# ZB204 register map
Vendor: GS; File version: 1.2
CPU: CM3 r2p0, little endian, MPU, no FPU, VTOR, 3 interrupt priority bits
Registers are 32-bit, read-write, reset 0x0 unless marked. A register's access mark holds for its fields unless they carry their own. Offsets are from the block's base; [hi:lo] are bit positions; {n}, {i} and the like mark numbered series.

## PIT_CHANNEL0 — Programmable Interrupt Timer Modules
Base 0x40070100
Same registers: PIT_CHANNEL1 0x40070110, PIT_CHANNEL2 0x40070120, PIT_CHANNEL3 0x40070130, PIT_CHANNEL4 0x40070140, PIT_CHANNEL5 0x40070150, PIT_CHANNEL6 0x40080100, PIT_CHANNEL7 0x40080110, PIT_CHANNEL8 0x40080120, PIT_CHANNEL9 0x40080130, PIT_CHANNEL10 0x40080140, PIT_CHANNEL11 0x40080150
0x00 LDVAL — Timer Load Value Register
0x04 CVAL — Current Timer Value Register
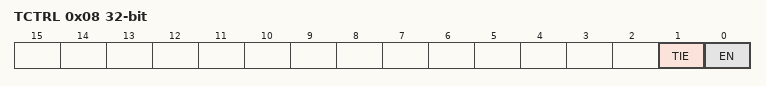
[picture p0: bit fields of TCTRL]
0x08 TCTRL — Timer Control Register
  [1] TIE — Timer Enable Bit
    0=disabled; 1=enabled
  [0] EN — Timer Interrupt Enable Bit
    0=disabled; 1=enabled
0x0C TFLG — Timer Flag Register
  [0] TIF — Time Interrupt Flag
    0=not occurred; 1=occurred

## CCM — Chip Configuration Module
Base 0x40010000
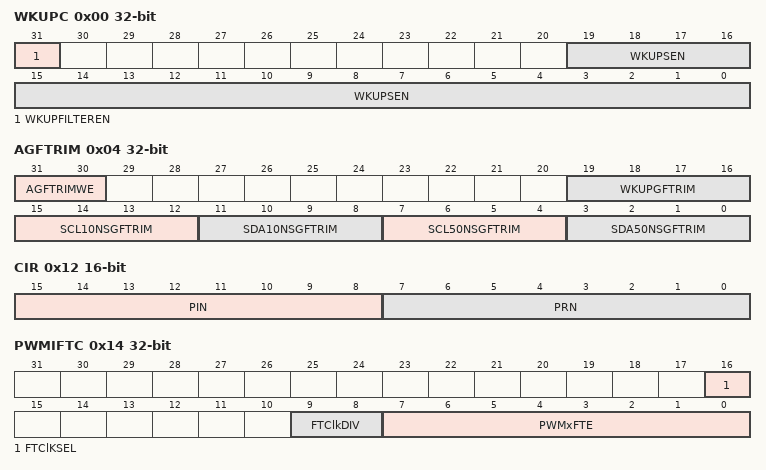
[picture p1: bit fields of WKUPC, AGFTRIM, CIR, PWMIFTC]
0x00 WKUPC — Wakeup Configuration Register
  [31] WKUPFILTEREN — Wakeup Source Filter Enable
    0=enable; 1=enable
  [19:0] WKUPSEN — Wakeup Source Enable
0x04 AGFTRIM — Analog Glitch Filter Trim Value Register
  [31:30] AGFTRIMWE — register write enable
  [19:16] WKUPGFTRIM — Trim value of the wakeup signal glitch filter
  [15:12] SCL10NSGFTRIM — Trim value of the 10ns glitch filter of I2C SCL pin
  [11:8] SDA10NSGFTRIM — Trim value of the 10ns glitch filter of I2C SDA pin
  [7:4] SCL50NSGFTRIM — Trim value of the 50ns glitch filter of I2C SCL pin
  [3:0] SDA50NSGFTRIM — Trim value of the 50ns glitch filter of I2C SDA pin
0x10 CTR 16-bit — Chip Test Register
0x12 CIR 16-bit — Chip Identification Register
  [15:8] PIN — Part Identification Number Field
  [7:0] PRN — Part Revision Number Field
0x14 PWMIFTC — PWM Filter Control
  [16] FTClKSEL — Filter Clock source selection
  [9:8] FTClkDIV — Divide the Filter Clock
  [7:0] PWMxFTE — Enable the PWMx pin input digital glitch filter
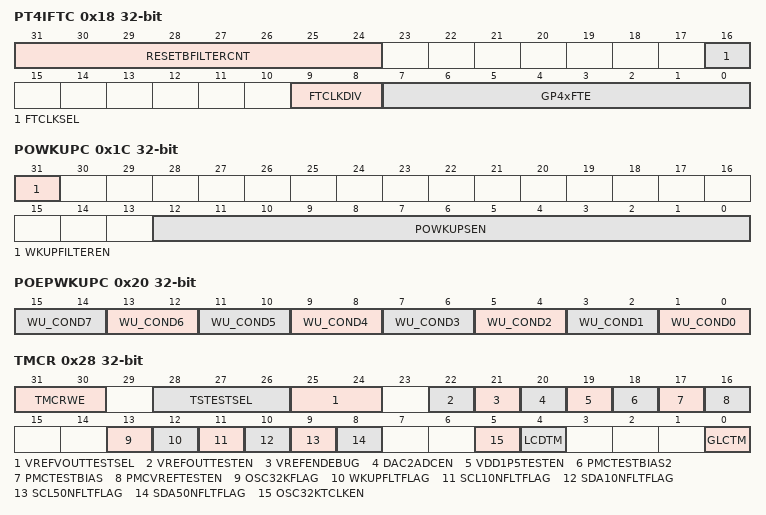
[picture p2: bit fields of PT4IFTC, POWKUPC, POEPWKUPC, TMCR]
0x18 PT4IFTC — PORT4 resetb Filter Control
  [31:24] RESETBFILTERCNT — Resetb Filter Counter Value
  [16] FTCLKSEL — Filter Clock source selection
  [9:8] FTCLKDIV — Divide the Filter Clock by (FTClkDIV+1)
  [7:0] GP4xFTE — Enable the GPIO4[x] pin input digital glitch filter
0x1C POWKUPC — PowerOff Mode Wakeup Configuration Register
  [31] WKUPFILTEREN — Wakeup Source Filter Enable
  [12:0] POWKUPSEN — PowerOff Wakeup Source Enable
0x20 POEPWKUPC — PowerOff Mode External Pins Wakeup Condition Register
  [2n+1:2n] WU_COND{n} (n=0..7) — WakeUp Cond
0x24 POEPWKUPF — PowerOff Mode External Pins Wakeup Flag Register
  [7:0] EPWKUPF — GPIO4x meets the wakeup condition
0x28 TMCR — Test Mode Register
  [31:30] TMCRWE — register write enable
  [28:26] TSTESTSEL — Select TS Test signal to sensebus
  [25:24] VREFVOUTTESTSEL — Select VREF Test signal to sensebus
  [22] VREFOUTTESTEN
  [21] VREFENDEBUG
  [20] DAC2ADCEN
  [19] VDD1P5TESTEN
  [18] PMCTESTBIAS2
  [17] PMCTESTBIAS
  [16] PMCVREFTESTEN
  [13] OSC32KFLAG — OSC32K Glitch Flag
  [12] WKUPFLTFLAG — Wakeup Source Glitch Filter Flag
  [11] SCL10NFLTFLAG — SCL 10ns Glitch Filter Flag
  [10] SDA10NFLTFLAG — SDA 10ns Glitch Filter Flag
  [9] SCL50NFLTFLAG — SCL 50ns Glitch Filter Flag
  [8] SDA50NFLTFLAG — SDA 50ns Glitch Filter Flag
  [5] OSC32KTCLKEN — Enable internal clock test of OSC32K
  [4] LCDTM — LCD Test Mode
  [0] GLCTM — Enable The Glitch Test Mode
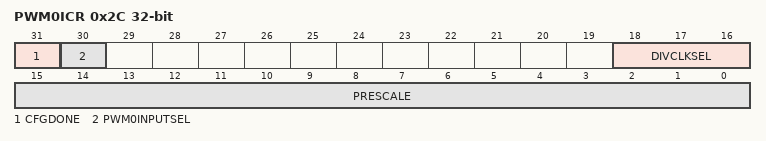
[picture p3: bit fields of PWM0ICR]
0x2C PWM0ICR — PWM Input Control register
  [31] CFGDONE — Configure of PWM0ICR register has been done
  [30] PWM0INPUTSEL — Select the input source of PWM0
  [18:16] DIVCLKSEL — Select the clock source of the divider
  [15:0] PRESCALE — Divide factor

## CPM — Clock and Power Control Module
Base 0x40030000
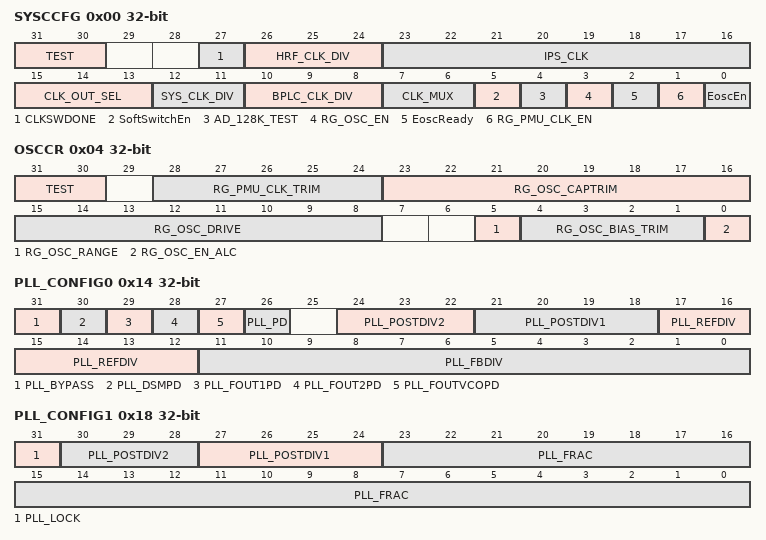
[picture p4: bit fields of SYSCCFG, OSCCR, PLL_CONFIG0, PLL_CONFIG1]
0x00 SYSCCFG
  [31:30] TEST — ADDRESS0TEST
  [27] CLKSWDONE
  [26:24] HRF_CLK_DIV
  [23:16] IPS_CLK
  [15:13] CLK_OUT_SEL
  [12:11] SYS_CLK_DIV
  [10:8] BPLC_CLK_DIV
  [7:6] CLK_MUX
  [5] SoftSwitchEn
  [4] AD_128K_TEST
  [3] RG_OSC_EN
  [2] EoscReady
  [1] RG_PMU_CLK_EN
  [0] EoscEn
0x04 OSCCR
  [31:30] TEST — ADDRESS0TEST
  [28:24] RG_PMU_CLK_TRIM
  [23:16] RG_OSC_CAPTRIM
  [15:8] RG_OSC_DRIVE
  [5] RG_OSC_RANGE
  [4:1] RG_OSC_BIAS_TRIM
  [0] RG_OSC_EN_ALC
0x08 MSCRSTOP
0x0C MSCR — Module Stop Control Register
0x14 PLL_CONFIG0
  [31] PLL_BYPASS, [30] PLL_DSMPD, [29] PLL_FOUT1PD, [28] PLL_FOUT2PD, [27] PLL_FOUTVCOPD, [26] PLL_PD, [24:22] PLL_POSTDIV2, [21:18] PLL_POSTDIV1, [17:12] PLL_REFDIV, [11:0] PLL_FBDIV
0x18 PLL_CONFIG1
  [31] PLL_LOCK, [30:28] PLL_POSTDIV2, [27:24] PLL_POSTDIV1, [23:0] PLL_FRAC
0x1C AHBMSCR
0x20 AHBMSCRSTOP
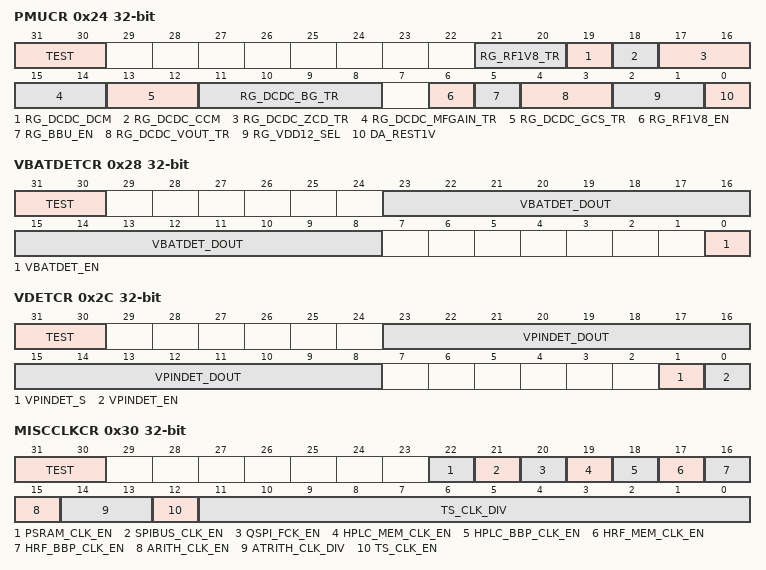
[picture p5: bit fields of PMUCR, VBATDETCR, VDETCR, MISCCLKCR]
0x24 PMUCR
  [31:30] TEST, [21:20] RG_RF1V8_TR, [19] RG_DCDC_DCM, [18] RG_DCDC_CCM, [17:16] RG_DCDC_ZCD_TR, [15:14] RG_DCDC_MFGAIN_TR, [13:12] RG_DCDC_GCS_TR, [11:8] RG_DCDC_BG_TR, [6] RG_RF1V8_EN, [5] RG_BBU_EN, [4:3] RG_DCDC_VOUT_TR, [2:1] RG_VDD12_SEL, [0] DA_REST1V
0x28 VBATDETCR
  [31:30] TEST
  [23:8] VBATDET_DOUT — VPINDET_DOUT
  [0] VBATDET_EN — VPINDET_EN
0x2C VDETCR
  [31:30] TEST, [23:8] VPINDET_DOUT, [1] VPINDET_S, [0] VPINDET_EN
0x30 MISCCLKCR
  [31:30] TEST — ADDRESS0TEST
  [22] PSRAM_CLK_EN
  [21] SPIBUS_CLK_EN
  [20] QSPI_FCK_EN
  [19] HPLC_MEM_CLK_EN
  [18] HPLC_BBP_CLK_EN
  [17] HRF_MEM_CLK_EN
  [16] HRF_BBP_CLK_EN
  [15] ARITH_CLK_EN
  [14:13] ATRITH_CLK_DIV
  [12] TS_CLK_EN
  [11:0] TS_CLK_DIV
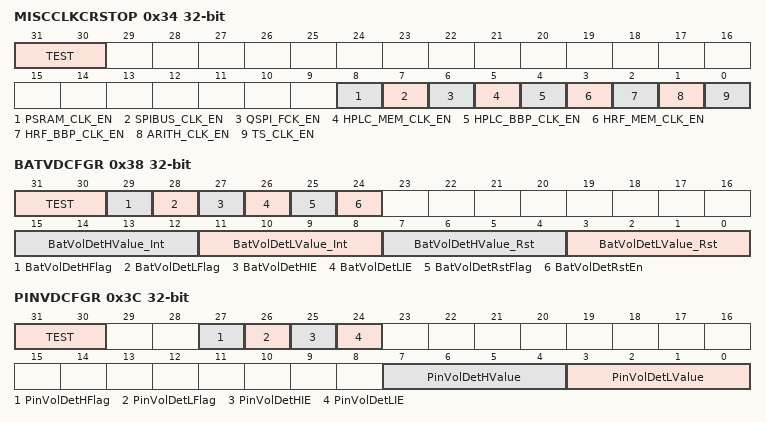
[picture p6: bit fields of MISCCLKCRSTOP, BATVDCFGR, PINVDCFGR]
0x34 MISCCLKCRSTOP
  [31:30] TEST — ADDRESS0TEST
  [8] PSRAM_CLK_EN
  [7] SPIBUS_CLK_EN
  [6] QSPI_FCK_EN
  [5] HPLC_MEM_CLK_EN
  [4] HPLC_BBP_CLK_EN
  [3] HRF_MEM_CLK_EN
  [2] HRF_BBP_CLK_EN
  [1] ARITH_CLK_EN
  [0] TS_CLK_EN
0x38 BATVDCFGR
  [31:30] TEST, [29] BatVolDetHFlag, [28] BatVolDetLFlag, [27] BatVolDetHIE, [26] BatVolDetLIE, [25] BatVolDetRstFlag, [24] BatVolDetRstEn, [15:12] BatVolDetHValue_Int, [11:8] BatVolDetLValue_Int, [7:4] BatVolDetHValue_Rst, [3:0] BatVolDetLValue_Rst
0x3C PINVDCFGR
  [31:30] TEST, [27] PinVolDetHFlag, [26] PinVolDetLFlag, [25] PinVolDetHIE, [24] PinVolDetLIE, [7:4] PinVolDetHValue, [3:0] PinVolDetLValue
